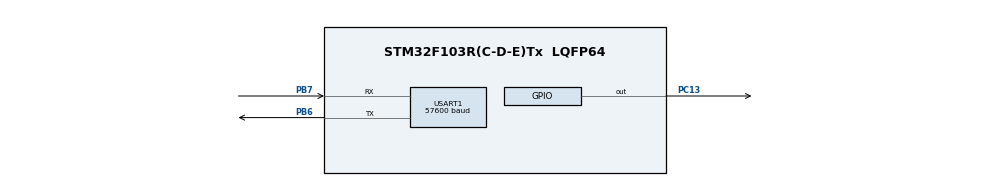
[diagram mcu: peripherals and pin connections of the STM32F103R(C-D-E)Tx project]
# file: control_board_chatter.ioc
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Dma.Request0=USART1_RX
Dma.Request1=USART1_TX
Dma.USART1_RX.0.Direction=DMA_PERIPH_TO_MEMORY
Dma.USART1_RX.0.Instance=DMA1_Channel5
Dma.USART1_RX.0.MemDataAlignment=DMA_MDATAALIGN_BYTE
Dma.USART1_RX.0.MemInc=DMA_MINC_ENABLE
Dma.USART1_RX.0.Mode=DMA_NORMAL
Dma.USART1_RX.0.PeriphDataAlignment=DMA_PDATAALIGN_BYTE
Dma.USART1_RX.0.PeriphInc=DMA_PINC_DISABLE
Dma.USART1_RX.0.Priority=DMA_PRIORITY_HIGH
Dma.USART1_TX.1.Direction=DMA_MEMORY_TO_PERIPH
Dma.USART1_TX.1.Instance=DMA1_Channel4
Dma.USART1_TX.1.MemDataAlignment=DMA_MDATAALIGN_BYTE
Dma.USART1_TX.1.MemInc=DMA_MINC_ENABLE
Dma.USART1_TX.1.Mode=DMA_NORMAL
Dma.USART1_TX.1.PeriphDataAlignment=DMA_PDATAALIGN_BYTE
Dma.USART1_TX.1.PeriphInc=DMA_PINC_DISABLE
Dma.USART1_TX.1.Priority=DMA_PRIORITY_HIGH
Mcu.Family=STM32F1
Mcu.Name=STM32F103R(C-D-E)Tx
Mcu.Package=LQFP64
NVIC.DMA1_Channel4_IRQn=true\:0\:0\:false\:false\:true\:false\:true\:true
NVIC.DMA1_Channel5_IRQn=true\:0\:0\:false\:false\:true\:false\:true\:true
NVIC.PriorityGroup=NVIC_PRIORITYGROUP_4
NVIC.USART1_IRQn=true\:0\:0\:false\:false\:true\:true\:true\:true
PA13.Mode=Serial_Wire
PA13.Signal=SYS_JTMS-SWDIO
PA14.Mode=Serial_Wire
PA14.Signal=SYS_JTCK-SWCLK
PB6.Mode=Asynchronous
PB6.Signal=USART1_TX
PB7.Mode=Asynchronous
PB7.Signal=USART1_RX
PC13-TAMPER-RTC.Signal=GPIO_Output
PD0-OSC_IN.Mode=HSE-External-Oscillator
PD0-OSC_IN.Signal=RCC_OSC_IN
PD1-OSC_OUT.Mode=HSE-External-Oscillator
PD1-OSC_OUT.Signal=RCC_OSC_OUT
ProjectManager.HeapSize=0x200
ProjectManager.StackSize=0x400
ProjectManager.TargetToolchain=STM32CubeIDE
RCC.APB1Freq_Value=8000000
RCC.APB2Freq_Value=8000000
USART1.BaudRate=57600
USART1.VirtualMode=VM_ASYNC
board=custom

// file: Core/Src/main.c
/* USER CODE BEGIN Header */
/**
  ******************************************************************************
  * @file           : main.c
  * @brief          : Main program body
  ******************************************************************************
  * @attention
  *
  * Copyright (c) 2024 STMicroelectronics.
  * All rights reserved.
  *
  * This software is licensed under terms that can be found in the LICENSE file
  * in the root directory of this software component.
  * If no LICENSE file comes with this software, it is provided AS-IS.
  *
  ******************************************************************************
  */
/* USER CODE END Header */
#include "main.h"

/* USER CODE BEGIN Includes */
#include "mainpp.h"
/* USER CODE END Includes */

UART_HandleTypeDef huart_rosserial;
DMA_HandleTypeDef hdma_usart1_rx;
DMA_HandleTypeDef hdma_usart1_tx;

/* USER CODE BEGIN PV */
uint8_t debug_buffer[13] = "Hello World!\n";
uint8_t debug_receive[10];
/* USER CODE END PV */

void SystemClock_Config(void);
static void MX_GPIO_Init(void);
static void MX_DMA_Init(void);
static void MX_USART1_UART_Init(void);

int main(void)
{

  /* MCU Configuration--------------------------------------------------------*/

  /* Reset of all peripherals, Initializes the Flash interface and the Systick. */
  HAL_Init();

  /* Configure the system clock */
  SystemClock_Config();

  /* Initialize all configured peripherals */
  MX_GPIO_Init();
  MX_DMA_Init();
  MX_USART1_UART_Init();
  /* USER CODE BEGIN 2 */
  setup();
  /* USER CODE END 2 */

  /* Infinite loop */
  while (1)
  {

    /* USER CODE BEGIN 3 */
	  loop();
	  //HAL_UART_Transmit_DMA(&huart_rosserial, debug_buffer, sizeof(debug_buffer));
	  //HAL_Delay(500);
  }
  /* USER CODE END 3 */
}

void SystemClock_Config(void)
{
  RCC_OscInitTypeDef RCC_OscInitStruct = {0};
  RCC_ClkInitTypeDef RCC_ClkInitStruct = {0};

  /** Initializes the RCC Oscillators according to the specified parameters
  * in the RCC_OscInitTypeDef structure.
  */
  RCC_OscInitStruct.OscillatorType = RCC_OSCILLATORTYPE_HSI;
  RCC_OscInitStruct.HSIState = RCC_HSI_ON;
  RCC_OscInitStruct.HSICalibrationValue = RCC_HSICALIBRATION_DEFAULT;
  RCC_OscInitStruct.PLL.PLLState = RCC_PLL_NONE;
  if (HAL_RCC_OscConfig(&RCC_OscInitStruct) != HAL_OK)
  {
    Error_Handler();
  }

  /** Initializes the CPU, AHB and APB buses clocks
  */
  RCC_ClkInitStruct.ClockType = RCC_CLOCKTYPE_HCLK|RCC_CLOCKTYPE_SYSCLK
                              |RCC_CLOCKTYPE_PCLK1|RCC_CLOCKTYPE_PCLK2;
  RCC_ClkInitStruct.SYSCLKSource = RCC_SYSCLKSOURCE_HSI;
  RCC_ClkInitStruct.AHBCLKDivider = RCC_SYSCLK_DIV1;
  RCC_ClkInitStruct.APB1CLKDivider = RCC_HCLK_DIV1;
  RCC_ClkInitStruct.APB2CLKDivider = RCC_HCLK_DIV1;

  if (HAL_RCC_ClockConfig(&RCC_ClkInitStruct, FLASH_LATENCY_0) != HAL_OK)
  {
    Error_Handler();
  }
}

static void MX_USART1_UART_Init(void)
{

  huart_rosserial.Instance = USART1;
  huart_rosserial.Init.BaudRate = 57600;
  huart_rosserial.Init.WordLength = UART_WORDLENGTH_8B;
  huart_rosserial.Init.StopBits = UART_STOPBITS_1;
  huart_rosserial.Init.Parity = UART_PARITY_NONE;
  huart_rosserial.Init.Mode = UART_MODE_TX_RX;
  huart_rosserial.Init.HwFlowCtl = UART_HWCONTROL_NONE;
  huart_rosserial.Init.OverSampling = UART_OVERSAMPLING_16;
  if (HAL_UART_Init(&huart_rosserial) != HAL_OK)
  {
    Error_Handler();
  }

}

static void MX_DMA_Init(void)
{

  /* DMA controller clock enable */
  __HAL_RCC_DMA1_CLK_ENABLE();

  /* DMA interrupt init */
  /* DMA1_Channel4_IRQn interrupt configuration */
  HAL_NVIC_SetPriority(DMA1_Channel4_IRQn, 0, 0);
  HAL_NVIC_EnableIRQ(DMA1_Channel4_IRQn);
  /* DMA1_Channel5_IRQn interrupt configuration */
  HAL_NVIC_SetPriority(DMA1_Channel5_IRQn, 0, 0);
  HAL_NVIC_EnableIRQ(DMA1_Channel5_IRQn);

}

static void MX_GPIO_Init(void)
{
  GPIO_InitTypeDef GPIO_InitStruct = {0};

  /* GPIO Ports Clock Enable */
  __HAL_RCC_GPIOC_CLK_ENABLE();
  __HAL_RCC_GPIOD_CLK_ENABLE();
  __HAL_RCC_GPIOA_CLK_ENABLE();
  __HAL_RCC_GPIOB_CLK_ENABLE();

  /*Configure GPIO pin Output Level */
  HAL_GPIO_WritePin(GPIOC, GPIO_PIN_13, GPIO_PIN_RESET);

  /*Configure GPIO pin : PC13 */
  GPIO_InitStruct.Pin = GPIO_PIN_13;
  GPIO_InitStruct.Mode = GPIO_MODE_OUTPUT_PP;
  GPIO_InitStruct.Pull = GPIO_NOPULL;
  GPIO_InitStruct.Speed = GPIO_SPEED_FREQ_LOW;
  HAL_GPIO_Init(GPIOC, &GPIO_InitStruct);

}

void Error_Handler(void)
{
  __disable_irq();
  while (1)
  {
  }
}
